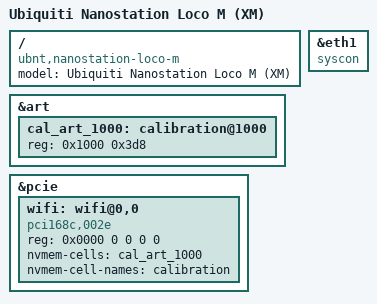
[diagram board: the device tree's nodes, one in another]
// SPDX-License-Identifier: GPL-2.0-or-later OR MIT

#include "ar7241.dtsi"
#include "ar724x_ubnt_xm.dtsi"
#include "ar724x_ubnt_xm_outdoor.dtsi"

/ {
	compatible = "ubnt,nanostation-loco-m", "ubnt,xm", "qca,ar7241";
	model = "Ubiquiti Nanostation Loco M (XM)";
};

&eth1 {
	compatible = "syscon", "simple-mfd";
};

&art {
	cal_art_1000: calibration@1000 {
		reg = <0x1000 0x3d8>;
	};
};

&pcie {
	wifi: wifi@0,0 {
		compatible = "pci168c,002e";
		reg = <0x0000 0 0 0 0>;
		nvmem-cells = <&cal_art_1000>;
		nvmem-cell-names = "calibration";
	};
};
